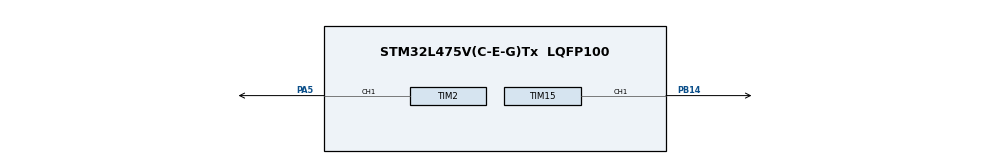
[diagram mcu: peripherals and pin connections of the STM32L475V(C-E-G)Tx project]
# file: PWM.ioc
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Mcu.Family=STM32L4
Mcu.Name=STM32L475V(C-E-G)Tx
Mcu.Package=LQFP100
NVIC.PriorityGroup=NVIC_PRIORITYGROUP_4
PA5.Signal=S_TIM2_CH1
PB14.Signal=S_TIM15_CH1
ProjectManager.HeapSize=0x200
ProjectManager.StackSize=0x400
ProjectManager.TargetToolchain=EWARM V8.32
RCC.HSE_VALUE=8000000
RCC.HSI_VALUE=16000000
RCC.LSE_VALUE=32768
RCC.MSI_VALUE=4000000
RCC.VCOOutputFreq_Value=32000000
SH.S_TIM15_CH1.0=TIM15_CH1,PWM Generation1 CH1
SH.S_TIM2_CH1.0=TIM2_CH1,PWM Generation1 CH1
TIM15.Channel-PWM\ Generation1\ CH1=TIM_CHANNEL_1
TIM15.Period=10000-1
TIM15.Prescaler=200-1
TIM15.Pulse-PWM\ Generation1\ CH1=1000
TIM2.Channel-PWM\ Generation1\ CH1=TIM_CHANNEL_1
TIM2.Period=2000-1
TIM2.Prescaler=20-1
TIM2.Pulse-PWM\ Generation1\ CH1=1500
VP_TIM15_VS_ClockSourceINT.Mode=Internal
VP_TIM2_VS_ClockSourceINT.Mode=Internal
board=custom

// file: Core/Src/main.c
/* USER CODE BEGIN Header */
/**
  ******************************************************************************
  * @file           : main.c
  * @brief          : Main program body
  ******************************************************************************
  * @attention
  *
  * <h2><center>&copy; Copyright (c) 2020 STMicroelectronics.
  * All rights reserved.</center></h2>
  *
  * This software component is licensed by ST under BSD 3-Clause license,
  * the "License"; You may not use this file except in compliance with the
  * License. You may obtain a copy of the License at:
  *                        opensource.org/licenses/BSD-3-Clause
  *
  ******************************************************************************
  */
/* USER CODE END Header */
#include "main.h"

TIM_HandleTypeDef htim2;
TIM_HandleTypeDef htim15;

void SystemClock_Config(void);
static void MX_GPIO_Init(void);
static void MX_TIM2_Init(void);
static void MX_TIM15_Init(void);

#if 1
// Exploring PWM on STM32L475 board
uint16_t pwm_value; // PWM change function call argument
int16_t step;;      // PWM change function call argument local variavle: change
                    // step size

void user_pwm_setvalue(uint16_t value);

void user_pwm_setvalue(uint16_t value)
{
    // next 3 lines of code are from Andrew Law's posting on DIscussion link
    // of EMBSYS 310 A course canvas site
    // without these 3 lines, the program stuck in HAL_TIM_PWM_ConfigChannel()
    // like an infinite loop
    // maybe due to priority disorder between interrupts
    // couldn't figured out the cause of problem yet
    HAL_TIM_PWM_Stop(&htim2, TIM_CHANNEL_1);
    htim2.Init.Period = 2000;
    HAL_TIM_PWM_Init(&htim2);

    // similar routine to MX_TIM2_Init()
    // used for TIM2 for LED1 PWM change demo
    TIM_OC_InitTypeDef sConfigOC;

    sConfigOC.OCMode = TIM_OCMODE_PWM1;
    sConfigOC.Pulse = value;
    sConfigOC.OCPolarity = TIM_OCPOLARITY_HIGH;
    sConfigOC.OCFastMode = TIM_OCFAST_DISABLE;
    HAL_TIM_PWM_ConfigChannel(&htim2, &sConfigOC, TIM_CHANNEL_1);
    HAL_TIM_PWM_Start(&htim2, TIM_CHANNEL_1);
    //HAL_TIM_MspPostInit(&htim2); //*********************//
}
#endif

int main(void)
{

  /* MCU Configuration--------------------------------------------------------*/

  /* Reset of all peripherals, Initializes the Flash interface and the Systick. */
  HAL_Init();

  /* Configure the system clock */
  SystemClock_Config();

  /* Initialize all configured peripherals */
  MX_GPIO_Init();
  MX_TIM2_Init();
  MX_TIM15_Init();
  /* USER CODE BEGIN 2 */
  HAL_TIM_PWM_Start(&htim2, TIM_CHANNEL_1); //Demo w/ PWM change with LED1/PA5
  HAL_TIM_PWM_Start(&htim15, TIM_CHANNEL_1); //Demo w/o PWM change at LED2/PB14

  /* USER CODE END 2 */

  /* Infinite loop */
  while (1)
  {

    /* USER CODE BEGIN 3 */
   // codes for infinite loop of LED1 blinking with changing PWM value
#if 1
  HAL_Delay(100);                       // up-down cycle of 2 sec: 20x100 msec
  if(pwm_value <= 0) step = 200;        // 10 steps increase: 1 sec (1x100 msec)
  if(pwm_value >= 2000) step = -200;    // 10 steps decrease: 1 sec (1x100 msec)
  pwm_value += step;
  user_pwm_setvalue(pwm_value);
#endif

  }
  /* USER CODE END 3 */
}

void SystemClock_Config(void)
{
  RCC_OscInitTypeDef RCC_OscInitStruct = {0};
  RCC_ClkInitTypeDef RCC_ClkInitStruct = {0};

  /** Initializes the RCC Oscillators according to the specified parameters
  * in the RCC_OscInitTypeDef structure.
  */
  RCC_OscInitStruct.OscillatorType = RCC_OSCILLATORTYPE_MSI;
  RCC_OscInitStruct.MSIState = RCC_MSI_ON;
  RCC_OscInitStruct.MSICalibrationValue = 0;
  RCC_OscInitStruct.MSIClockRange = RCC_MSIRANGE_6;
  RCC_OscInitStruct.PLL.PLLState = RCC_PLL_NONE;
  if (HAL_RCC_OscConfig(&RCC_OscInitStruct) != HAL_OK)
  {
    Error_Handler();
  }
  /** Initializes the CPU, AHB and APB buses clocks
  */
  RCC_ClkInitStruct.ClockType = RCC_CLOCKTYPE_HCLK|RCC_CLOCKTYPE_SYSCLK
                              |RCC_CLOCKTYPE_PCLK1|RCC_CLOCKTYPE_PCLK2;
  RCC_ClkInitStruct.SYSCLKSource = RCC_SYSCLKSOURCE_MSI;
  RCC_ClkInitStruct.AHBCLKDivider = RCC_SYSCLK_DIV1;
  RCC_ClkInitStruct.APB1CLKDivider = RCC_HCLK_DIV1;
  RCC_ClkInitStruct.APB2CLKDivider = RCC_HCLK_DIV1;

  if (HAL_RCC_ClockConfig(&RCC_ClkInitStruct, FLASH_LATENCY_0) != HAL_OK)
  {
    Error_Handler();
  }
  /** Configure the main internal regulator output voltage
  */
  if (HAL_PWREx_ControlVoltageScaling(PWR_REGULATOR_VOLTAGE_SCALE1) != HAL_OK)
  {
    Error_Handler();
  }
}

static void MX_TIM2_Init(void)
{

  TIM_ClockConfigTypeDef sClockSourceConfig = {0};
  TIM_MasterConfigTypeDef sMasterConfig = {0};
  TIM_OC_InitTypeDef sConfigOC = {0};

  htim2.Instance = TIM2;
  htim2.Init.Prescaler = 20-1;
  htim2.Init.CounterMode = TIM_COUNTERMODE_UP;
  htim2.Init.Period = 2000-1;
  htim2.Init.ClockDivision = TIM_CLOCKDIVISION_DIV1;
  htim2.Init.AutoReloadPreload = TIM_AUTORELOAD_PRELOAD_DISABLE;
  if (HAL_TIM_Base_Init(&htim2) != HAL_OK)
  {
    Error_Handler();
  }
  sClockSourceConfig.ClockSource = TIM_CLOCKSOURCE_INTERNAL;
  if (HAL_TIM_ConfigClockSource(&htim2, &sClockSourceConfig) != HAL_OK)
  {
    Error_Handler();
  }
  if (HAL_TIM_PWM_Init(&htim2) != HAL_OK)
  {
    Error_Handler();
  }
  sMasterConfig.MasterOutputTrigger = TIM_TRGO_RESET;
  sMasterConfig.MasterSlaveMode = TIM_MASTERSLAVEMODE_DISABLE;
  if (HAL_TIMEx_MasterConfigSynchronization(&htim2, &sMasterConfig) != HAL_OK)
  {
    Error_Handler();
  }
  sConfigOC.OCMode = TIM_OCMODE_PWM1;
  sConfigOC.Pulse = 1500;
  sConfigOC.OCPolarity = TIM_OCPOLARITY_HIGH;
  sConfigOC.OCFastMode = TIM_OCFAST_DISABLE;
  if (HAL_TIM_PWM_ConfigChannel(&htim2, &sConfigOC, TIM_CHANNEL_1) != HAL_OK)
  {
    Error_Handler();
  }
  HAL_TIM_MspPostInit(&htim2);

}

static void MX_TIM15_Init(void)
{

  TIM_ClockConfigTypeDef sClockSourceConfig = {0};
  TIM_MasterConfigTypeDef sMasterConfig = {0};
  TIM_OC_InitTypeDef sConfigOC = {0};
  TIM_BreakDeadTimeConfigTypeDef sBreakDeadTimeConfig = {0};

  htim15.Instance = TIM15;
  htim15.Init.Prescaler = 200-1;
  htim15.Init.CounterMode = TIM_COUNTERMODE_UP;
  htim15.Init.Period = 10000-1;
  htim15.Init.ClockDivision = TIM_CLOCKDIVISION_DIV1;
  htim15.Init.RepetitionCounter = 0;
  htim15.Init.AutoReloadPreload = TIM_AUTORELOAD_PRELOAD_DISABLE;
  if (HAL_TIM_Base_Init(&htim15) != HAL_OK)
  {
    Error_Handler();
  }
  sClockSourceConfig.ClockSource = TIM_CLOCKSOURCE_INTERNAL;
  if (HAL_TIM_ConfigClockSource(&htim15, &sClockSourceConfig) != HAL_OK)
  {
    Error_Handler();
  }
  if (HAL_TIM_PWM_Init(&htim15) != HAL_OK)
  {
    Error_Handler();
  }
  sMasterConfig.MasterOutputTrigger = TIM_TRGO_RESET;
  sMasterConfig.MasterSlaveMode = TIM_MASTERSLAVEMODE_DISABLE;
  if (HAL_TIMEx_MasterConfigSynchronization(&htim15, &sMasterConfig) != HAL_OK)
  {
    Error_Handler();
  }
  sConfigOC.OCMode = TIM_OCMODE_PWM1;
  sConfigOC.Pulse = 1000;
  sConfigOC.OCPolarity = TIM_OCPOLARITY_HIGH;
  sConfigOC.OCNPolarity = TIM_OCNPOLARITY_HIGH;
  sConfigOC.OCFastMode = TIM_OCFAST_DISABLE;
  sConfigOC.OCIdleState = TIM_OCIDLESTATE_RESET;
  sConfigOC.OCNIdleState = TIM_OCNIDLESTATE_RESET;
  if (HAL_TIM_PWM_ConfigChannel(&htim15, &sConfigOC, TIM_CHANNEL_1) != HAL_OK)
  {
    Error_Handler();
  }
  sBreakDeadTimeConfig.OffStateRunMode = TIM_OSSR_DISABLE;
  sBreakDeadTimeConfig.OffStateIDLEMode = TIM_OSSI_DISABLE;
  sBreakDeadTimeConfig.LockLevel = TIM_LOCKLEVEL_OFF;
  sBreakDeadTimeConfig.DeadTime = 0;
  sBreakDeadTimeConfig.BreakState = TIM_BREAK_DISABLE;
  sBreakDeadTimeConfig.BreakPolarity = TIM_BREAKPOLARITY_HIGH;
  sBreakDeadTimeConfig.AutomaticOutput = TIM_AUTOMATICOUTPUT_DISABLE;
  if (HAL_TIMEx_ConfigBreakDeadTime(&htim15, &sBreakDeadTimeConfig) != HAL_OK)
  {
    Error_Handler();
  }
  HAL_TIM_MspPostInit(&htim15);

}

static void MX_GPIO_Init(void)
{

  /* GPIO Ports Clock Enable */
  __HAL_RCC_GPIOA_CLK_ENABLE();
  __HAL_RCC_GPIOB_CLK_ENABLE();

}

void Error_Handler(void)
{
}

/************************ (C) COPYRIGHT STMicroelectronics *****END OF FILE****/
